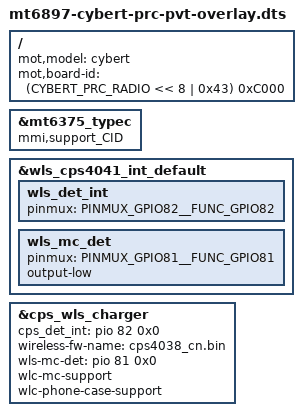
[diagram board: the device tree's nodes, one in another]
/* Copyright (c) 2023, Motorola Mobility Inc. All rights reserved.
 *
 * This program is free software; you can redistribute it and/or modify
 * it under the terms of the GNU General Public License version 2 and
 * only version 2 as published by the Free Software Foundation.
 *
 * This program is distributed in the hope that it will be useful,
 * but WITHOUT ANY WARRANTY; without even the implied warranty of
 * MERCHANTABILITY or FITNESS FOR A PARTICULAR PURPOSE.  See the
 * GNU General Public License for more details.
 */

/dts-v1/;
/plugin/;

#include "mediatek/mt6897-cybert-common-overlay.dtsi"
#include "cybert-sar-dvt2.dtsi"

#define CYBERT_PRC_RADIO 2

/* Board match root node */
/ {
	fragment@model {
		target-path = "/";
		__overlay__ {
			mot,model = "cybert";
			mot,board-id = <(CYBERT_PRC_RADIO << 8 | 0x43) 0xC000>;
		};
	};
};

&mt6375_typec {
       mmi,support_CID;
};

&wls_cps4041_int_default {
    wls_det_int {
        pinmux = <PINMUX_GPIO82__FUNC_GPIO82>;
    };
    wls_mc_det {
        pinmux = <PINMUX_GPIO81__FUNC_GPIO81>;
        output-low;
    };
};

&cps_wls_charger {
    cps_det_int = <&pio 82 0x0>;
    wireless-fw-name = "cps4038_cn.bin";
    wls-mc-det = <&pio 81 0x0>;
    wlc-mc-support;
    wlc-phone-case-support;
};

#include <cybert_evb/cust.dtsi>
#include "mediatek/cust_cybert_camera_v4l2.dtsi"
/*End of this file, DO NOT ADD ANYTHING HERE*/
